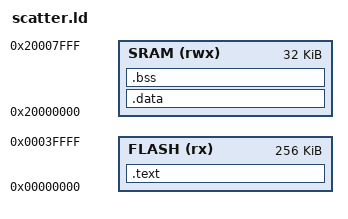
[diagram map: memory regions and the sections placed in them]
 /*
 * Copyright (c) 2015, Martin Jaros <xjaros32@stud.feec.vutbr.cz>
 *
 * Permission to use, copy, modify, and/or distribute this software for any
 * purpose with or without fee is hereby granted, provided that the above
 * copyright notice and this permission notice appear in all copies.
 *
 * THE SOFTWARE IS PROVIDED "AS IS" AND THE AUTHOR DISCLAIMS ALL WARRANTIES
 * WITH REGARD TO THIS SOFTWARE INCLUDING ALL IMPLIED WARRANTIES OF
 * MERCHANTABILITY AND FITNESS. IN NO EVENT SHALL THE AUTHOR BE LIABLE FOR
 * ANY SPECIAL, DIRECT, INDIRECT, OR CONSEQUENTIAL DAMAGES OR ANY DAMAGES
 * WHATSOEVER RESULTING FROM LOSS OF USE, DATA OR PROFITS, WHETHER IN AN
 * ACTION OF CONTRACT, NEGLIGENCE OR OTHER TORTIOUS ACTION, ARISING OUT OF
 * OR IN CONNECTION WITH THE USE OR PERFORMANCE OF THIS SOFTWARE.
 */

 /*
 * Copyright (c) 2018, Piyush Itankar <pitankar@gmail.com>
 *
 * Permission to use, copy, modify, and/or distribute this software for any
 * purpose with or without fee is hereby granted, provided that the above
 * copyright notice and this permission notice appear in all copies.
 *
 * THE SOFTWARE IS PROVIDED "AS IS" AND THE AUTHOR DISCLAIMS ALL WARRANTIES
 * WITH REGARD TO THIS SOFTWARE INCLUDING ALL IMPLIED WARRANTIES OF
 * MERCHANTABILITY AND FITNESS. IN NO EVENT SHALL THE AUTHOR BE LIABLE FOR
 * ANY SPECIAL, DIRECT, INDIRECT, OR CONSEQUENTIAL DAMAGES OR ANY DAMAGES
 * WHATSOEVER RESULTING FROM LOSS OF USE, DATA OR PROFITS, WHETHER IN AN
 * ACTION OF CONTRACT, NEGLIGENCE OR OTHER TORTIOUS ACTION, ARISING OUT OF
 * OR IN CONNECTION WITH THE USE OR PERFORMANCE OF THIS SOFTWARE.
 */

MEMORY
{
    FLASH (rx) : ORIGIN = 0x00000000, LENGTH = 0x00040000
    SRAM (rwx) : ORIGIN = 0x20000000, LENGTH = 0x00008000
}

SECTIONS
{
    .text :
    {
        _text = .;
        KEEP(*(.isr_vector))
        *(.text*)
        *(.rodata*)
        _etext = .;
    } > FLASH

    .data : AT(ADDR(.text) + SIZEOF(.text))
    {
        _data = .;
        *(vtable)
        *(.data*)
        _edata = .;
    } > SRAM

    .bss :
    {
        _bss = .;
        *(.bss*)
        *(COMMON)
        _ebss = .;
    } > SRAM
}
